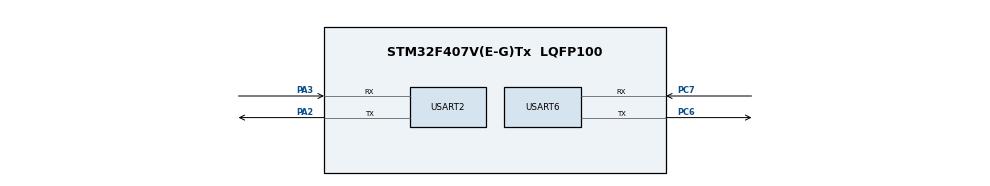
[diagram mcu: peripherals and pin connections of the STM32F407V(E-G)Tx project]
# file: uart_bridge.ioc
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FREERTOS.Mutexes01=uart2_mutex,Dynamic,NULL;uart6_mutex,Dynamic,NULL
FREERTOS.Queues01=uart2_to_uart6_queue,16,uint8_t,0,Dynamic,NULL,NULL;uart6_to_uart2_queue,16,uint8_t,0,Dynamic,NULL,NULL
FREERTOS.Tasks01=defaultTask,24,128,StartDefaultTask,Default,NULL,Dynamic,NULL,NULL;uart6_task,24,128,uart6_task_func,Default,NULL,Dynamic,NULL,NULL;uart2_task,24,128,uart2_task_func,Default,NULL,Dynamic,NULL,NULL
FREERTOS.configUSE_NEWLIB_REENTRANT=1
Mcu.Family=STM32F4
Mcu.Name=STM32F407V(E-G)Tx
Mcu.Package=LQFP100
NVIC.PriorityGroup=NVIC_PRIORITYGROUP_4
NVIC.USART2_IRQn=true\:5\:0\:false\:false\:true\:true\:true\:true\:true
NVIC.USART6_IRQn=true\:5\:0\:false\:false\:true\:true\:true\:true\:true
PA2.Mode=Asynchronous
PA2.Signal=USART2_TX
PA3.Mode=Asynchronous
PA3.Signal=USART2_RX
PC6.Mode=Asynchronous
PC6.Signal=USART6_TX
PC7.Mode=Asynchronous
PC7.Signal=USART6_RX
PH0-OSC_IN.Mode=HSE-External-Oscillator
PH0-OSC_IN.Signal=RCC_OSC_IN
PH1-OSC_OUT.Mode=HSE-External-Oscillator
PH1-OSC_OUT.Signal=RCC_OSC_OUT
ProjectManager.HeapSize=0x200
ProjectManager.StackSize=0x400
ProjectManager.TargetToolchain=STM32CubeIDE
RCC.48MHZClocksFreq_Value=84000000
RCC.AHBFreq_Value=168000000
RCC.APB1CLKDivider=RCC_HCLK_DIV4
RCC.APB1Freq_Value=42000000
RCC.APB1TimFreq_Value=84000000
RCC.APB2CLKDivider=RCC_HCLK_DIV2
RCC.APB2Freq_Value=84000000
RCC.APB2TimFreq_Value=168000000
RCC.CortexFreq_Value=168000000
RCC.HCLKFreq_Value=168000000
RCC.HSE_VALUE=8000000
RCC.HSI_VALUE=16000000
RCC.LSE_VALUE=32768
RCC.PLLM=4
RCC.PLLN=168
RCC.PLLSourceVirtual=RCC_PLLSOURCE_HSE
RCC.SYSCLKFreq_VALUE=168000000
RCC.SYSCLKSource=RCC_SYSCLKSOURCE_PLLCLK
RCC.VCOOutputFreq_Value=336000000
USART2.VirtualMode=VM_ASYNC
USART6.VirtualMode=VM_ASYNC
VP_FREERTOS_VS_CMSIS_V2.Mode=CMSIS_V2
board=custom

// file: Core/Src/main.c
/* USER CODE BEGIN Header */
/**
 ******************************************************************************
 * @file           : main.c
 * @brief          : Main program body
 ******************************************************************************
 * @attention
 *
 * Copyright (c) 2023 STMicroelectronics.
 * All rights reserved.
 *
 * This software is licensed under terms that can be found in the LICENSE file
 * in the root directory of this software component.
 * If no LICENSE file comes with this software, it is provided AS-IS.
 *
 ******************************************************************************
 */
/* USER CODE END Header */
#include "main.h"

/* USER CODE BEGIN Includes */
#include "uart.h"
#include "clk.h"
#include "gpio.h"
/* USER CODE END Includes */

/* Definitions for defaultTask */
osThreadId_t defaultTaskHandle;
const osThreadAttr_t defaultTask_attributes = { .name = "defaultTask",
		.stack_size = DEFAULT_TASK_STACK_SIZE, .priority = (osPriority_t) osPriorityNormal, };

void StartDefaultTask(void *argument);

int main(void) {

	/* MCU Configuration--------------------------------------------------------*/

	/* Reset of all peripherals, Initializes the Flash interface and the Systick. */
	HAL_Init();

	/* Configure the system clock */
	SystemClock_Config();

	/* Initialize all configured peripherals */
	MX_GPIO_Init();
	MX_USART2_UART_Init();
	MX_USART6_UART_Init();

	/* Init scheduler */
	osKernelInitialize();
	/* creation of defaultTask */
	defaultTaskHandle = osThreadNew(StartDefaultTask, NULL,
			&defaultTask_attributes);

	uart2_task_init();
	uart6_task_init();

	/* Start scheduler */
	osKernelStart();

	/* We should never get here as control is now taken by the scheduler */
	/* Infinite loop */
	while (1) {

	}
}

void StartDefaultTask(void *argument) {
	for (;;) {
		osDelay(1);
	}
}
void Error_Handler(void) {
	__disable_irq();
	while (1) {
	}
}
